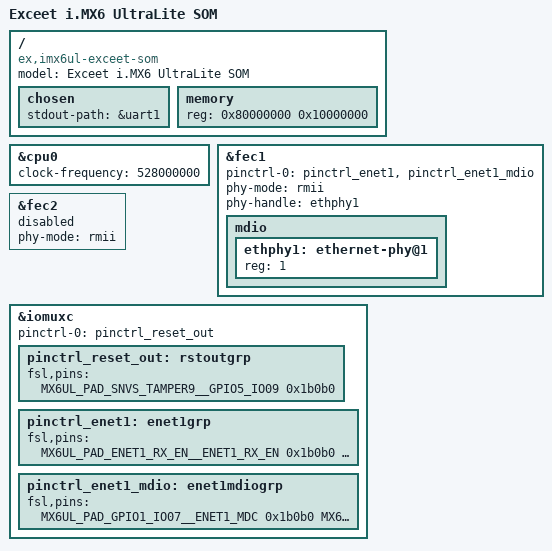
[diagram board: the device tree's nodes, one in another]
/*
 * Copyright (C) 2017 exceet electronics GmbH
 *
 * This program is free software; you can redistribute it and/or modify
 * it under the terms of the GNU General Public License version 2 as
 * published by the Free Software Foundation.
 */
#include "imx6ul.dtsi"

/ {
	model = "Exceet i.MX6 UltraLite SOM";
	compatible = "ex,imx6ul-exceet-som", "fsl,imx6ul";

	chosen {
		stdout-path = &uart1;
	};

	memory {
		reg = <0x80000000 0x10000000>;
	};
};

&cpu0 {
	clock-frequency = <528000000>;
};

&fec1 {
	pinctrl-names = "default";
	pinctrl-0 = <&pinctrl_enet1 &pinctrl_enet1_mdio>;
	phy-mode = "rmii";
	phy-handle = <&ethphy1>;
	status = "okay";

	mdio {
		#address-cells = <1>;
		#size-cells = <0>;

		ethphy1: ethernet-phy@1 {
			reg = <1>;
		};
	};
};

&fec2 {
	phy-mode = "rmii";
	status = "disabled";
};

&iomuxc {
	pinctrl-names = "default";
	pinctrl-0 = <&pinctrl_reset_out>;

	pinctrl_reset_out: rstoutgrp {
		fsl,pins = <
			MX6UL_PAD_SNVS_TAMPER9__GPIO5_IO09      0x1b0b0
		>;
	};

	pinctrl_enet1: enet1grp {
		fsl,pins = <
			MX6UL_PAD_ENET1_RX_EN__ENET1_RX_EN      0x1b0b0
			MX6UL_PAD_ENET1_RX_ER__ENET1_RX_ER      0x1b0b0
			MX6UL_PAD_ENET1_RX_DATA0__ENET1_RDATA00 0x1b0b0
			MX6UL_PAD_ENET1_RX_DATA1__ENET1_RDATA01 0x1b0b0
			MX6UL_PAD_ENET1_TX_EN__ENET1_TX_EN      0x1b0b0
			MX6UL_PAD_ENET1_TX_DATA0__ENET1_TDATA00 0x1b0b0
			MX6UL_PAD_ENET1_TX_DATA1__ENET1_TDATA01 0x1b0b0
			MX6UL_PAD_ENET1_TX_CLK__ENET1_REF_CLK1  0x4001b031
		>;
	};

	pinctrl_enet1_mdio: enet1mdiogrp {
		fsl,pins = <
			MX6UL_PAD_GPIO1_IO07__ENET1_MDC         0x1b0b0
			MX6UL_PAD_GPIO1_IO06__ENET1_MDIO        0x1b0b0
		>;
	};
};
